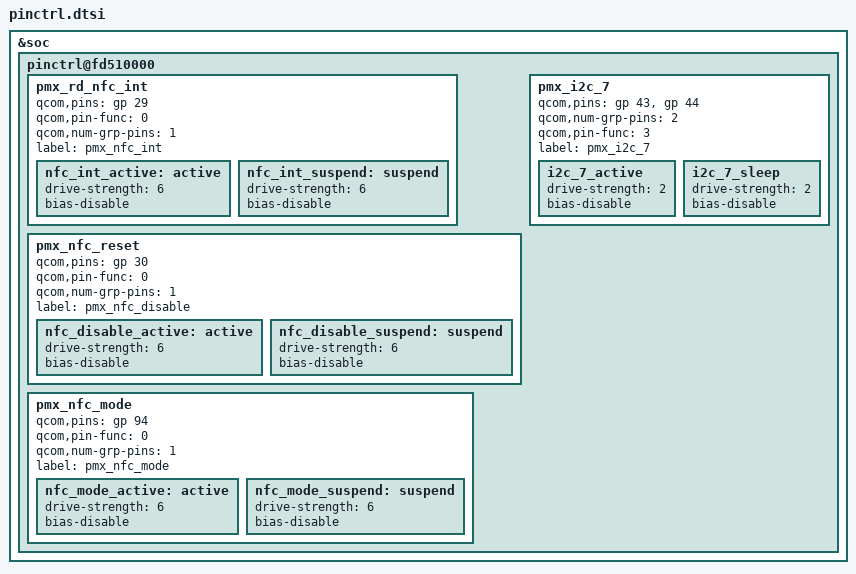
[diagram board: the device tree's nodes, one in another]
&soc {
	pinctrl@fd510000 {

        /* NFC Start */
		pmx_rd_nfc_int{
			qcom,pins = <&gp 29>;
			qcom,pin-func = <0>;
			qcom,num-grp-pins = <1>;
			label = "pmx_nfc_int";

			nfc_int_active: active {
				drive-strength = <6>;
				bias-disable;
			};

			nfc_int_suspend: suspend {
				drive-strength = <6>;
				bias-disable;
			};
		};

		pmx_nfc_reset{
			qcom,pins = <&gp 30>;
			qcom,pin-func = <0>;
			qcom,num-grp-pins = <1>;
			label = "pmx_nfc_disable";

			nfc_disable_active: active {
				drive-strength = <6>;
				bias-disable;
			};

			nfc_disable_suspend: suspend {
				drive-strength = <6>;
				bias-disable;
			};
		};

		pmx_nfc_mode{
			qcom,pins = <&gp 94>;
			qcom,pin-func = <0>;
			qcom,num-grp-pins = <1>;
			label = "pmx_nfc_mode";

			nfc_mode_active: active {
				drive-strength = <6>;
				bias-disable;
			};

			nfc_mode_suspend: suspend {
				drive-strength = <6>;
				bias-disable;
			};
		};
        /* NFC End */

		pmx_i2c_7 {
			qcom,pins = <&gp 43>, <&gp 44>; /* SDA, SCL */
			qcom,num-grp-pins = <2>;
			qcom,pin-func = <3>;
			label = "pmx_i2c_7";
	
			i2c_7_active: i2c_7_active {
				drive-strength = <2>;
				bias-disable;
			};
	
			i2c_7_sleep: i2c_7_sleep {
				drive-strength = <2>;
				bias-disable;
			};
		};
	};
};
